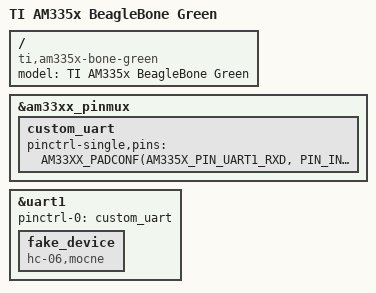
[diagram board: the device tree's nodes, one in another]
// SPDX-License-Identifier: GPL-2.0-only
/*
 * Copyright (C) 2012 Texas Instruments Incorporated - https://www.ti.com/
 */
/dts-v1/;

#include "am33xx.dtsi"
#include "am335x-bone-common.dtsi"
#include "am335x-bonegreen-common.dtsi"

/ {
	model = "TI AM335x BeagleBone Green";
	compatible = "ti,am335x-bone-green", "ti,am335x-bone-black", "ti,am335x-bone", "ti,am33xx";	
};

&am33xx_pinmux {
	custom_uart: custom_uart {
        pinctrl-single,pins = <
            AM33XX_PADCONF(AM335X_PIN_UART1_RXD, PIN_INPUT_PULLUP, MUX_MODE0)
            AM33XX_PADCONF(AM335X_PIN_UART1_TXD, PIN_OUTPUT_PULLDOWN, MUX_MODE0)
        >;
    };
};

&uart1 {
	pinctrl-names = "default";
	pinctrl-0 = <&custom_uart>;
	status = "okay";

	fake_device {
		compatible = "hc-06,mocne";
		status = "okay";
	};
};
